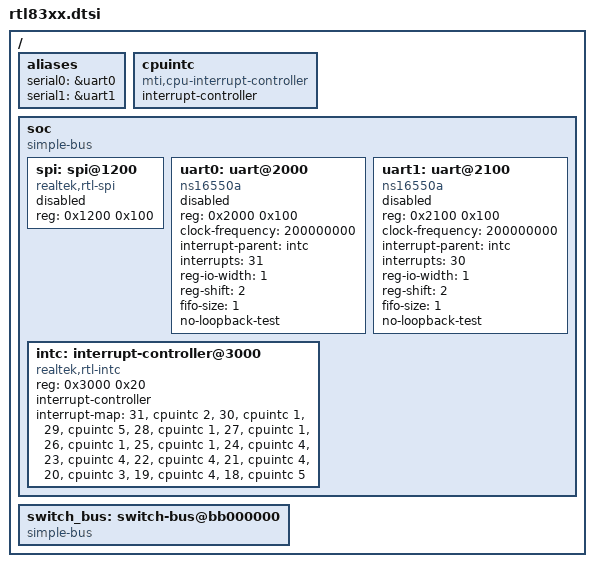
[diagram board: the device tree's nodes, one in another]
// SPDX-License-Identifier: GPL-2.0-or-later OR BSD-2-Clause

/ {
	#address-cells = <1>;
	#size-cells = <1>;

	aliases {
		serial0 = &uart0;
		serial1 = &uart1;
	};

	cpuintc: cpuintc {
		compatible = "mti,cpu-interrupt-controller";
		#address-cells = <0>;
		#interrupt-cells = <1>;
		interrupt-controller;
	};

	soc {
		compatible = "simple-bus";
		#address-cells = <1>;
		#size-cells = <1>;
		ranges = <0x0 0xb8000000 0x10000>;

		spi: spi@1200 {
			compatible = "realtek,rtl-spi";
			reg = <0x1200 0x100>;

			#address-cells = <1>;
			#size-cells = <0>;

			status = "disabled";
		};

		uart0: uart@2000 {
			compatible = "ns16550a";
			reg = <0x2000 0x100>;

			clock-frequency = <200000000>;

			interrupt-parent = <&intc>;
			interrupts = <31>;

			reg-io-width = <1>;
			reg-shift = <2>;
			fifo-size = <1>;
			no-loopback-test;

			status = "disabled";
		};

		uart1: uart@2100 {
			compatible = "ns16550a";
			reg = <0x2100 0x100>;

			clock-frequency = <200000000>;

			interrupt-parent = <&intc>;
			interrupts = <30>;

			reg-io-width = <1>;
			reg-shift = <2>;
			fifo-size = <1>;
			no-loopback-test;

			status = "disabled";
		};

		intc: interrupt-controller@3000 {
			compatible = "realtek,rtl-intc";
			reg = <0x3000 0x20>;
			interrupt-controller;
			#interrupt-cells = <1>;
			#address-cells = <0>;

			interrupt-map =
				<31 &cpuintc 2>, /* UART0 */
				<30 &cpuintc 1>, /* UART1 */
				<29 &cpuintc 5>, /* TC0 */
				<28 &cpuintc 1>, /* TC1 */
				<27 &cpuintc 1>, /* OCPTO */
				<26 &cpuintc 1>, /* HLXTO */
				<25 &cpuintc 1>, /* SLXTO */
				<24 &cpuintc 4>, /* NIC */
				<23 &cpuintc 4>, /* GPIO ABCD*/
				<22 &cpuintc 4>, /* GPIO EFGH*/
				<21 &cpuintc 4>, /* RTC */
				<20 &cpuintc 3>, /* SWCORE */
				<19 &cpuintc 4>, /* WFT IP1 */
				<18 &cpuintc 5>; /* WDT IP2 */
		};
	};

	switch_bus: switch-bus@bb000000 {
		compatible = "simple-bus";
		#address-cells = <1>;
		#size-cells = <1>;
		ranges = <0x0 0xbb000000 0x10000>;
	};
};
